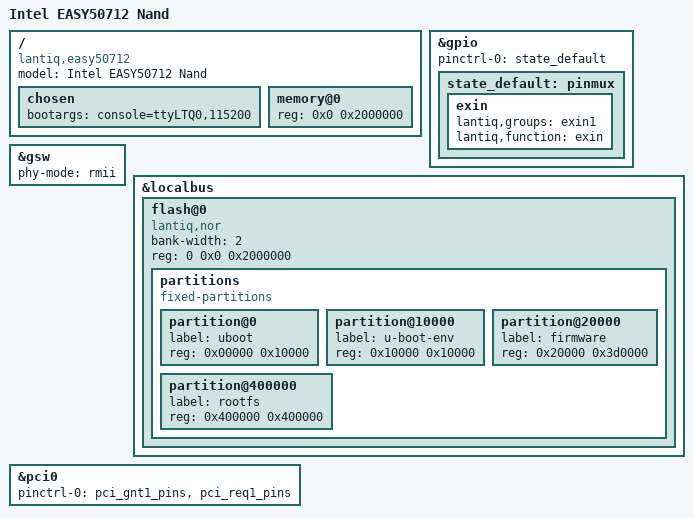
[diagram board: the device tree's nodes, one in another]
/dts-v1/;

#include "danube.dtsi"

/ {
	compatible = "lantiq,easy50712", "lantiq,xway", "lantiq,danube";
	model = "Intel EASY50712 Nand";

	chosen {
		bootargs = "console=ttyLTQ0,115200";
	};

	memory@0 {
		device_type = "memory";
		reg = <0x0 0x2000000>;
	};
};

&gpio {
	pinctrl-names = "default";
	pinctrl-0 = <&state_default>;

	state_default: pinmux {
		exin {
			lantiq,groups = "exin1";
			lantiq,function = "exin";
		};
	};
};

&gsw {
	phy-mode = "rmii";
};

&localbus {
	flash@0 {
		compatible = "lantiq,nor";
		bank-width = <2>;
		reg = <0 0x0 0x2000000>;

		partitions {
			compatible = "fixed-partitions";
			#address-cells = <1>;
			#size-cells = <1>;

			partition@0 {
				label = "uboot";
				reg = <0x00000 0x10000>; /* 64 KB */
			};

			partition@10000 {
				label = "u-boot-env";
				reg = <0x10000 0x10000>; /* 64 KB */
			};

			partition@20000 {
				label = "firmware";
				reg = <0x20000 0x3d0000>;
			};

			partition@400000 {
				label = "rootfs";
				reg = <0x400000 0x400000>;
			};
		};
	};
};

&pci0 {
	pinctrl-0 = <&pci_gnt1_pins>, <&pci_req1_pins>;
	pinctrl-names = "default";
};
